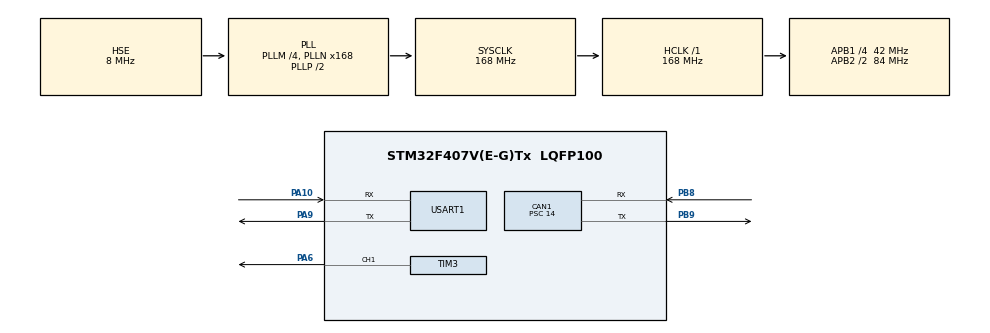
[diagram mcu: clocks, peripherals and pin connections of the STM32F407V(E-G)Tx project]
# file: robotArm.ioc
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CAN1.BS1=CAN_BS1_4TQ
CAN1.CalculateBaudRate=499999
CAN1.CalculateTimeBit=2000
CAN1.CalculateTimeQuantum=333.33333333333337
CAN1.Prescaler=14
FREERTOS.Tasks01=defaultTask,24,2048,StartDefaultTask,Default,NULL,Dynamic,NULL,NULL
FREERTOS.configENABLE_FPU=1
FREERTOS.configTOTAL_HEAP_SIZE=65536
Mcu.Family=STM32F4
Mcu.Name=STM32F407V(E-G)Tx
Mcu.Package=LQFP100
NVIC.CAN1_RX0_IRQn=true\:5\:0\:false\:false\:true\:true\:true\:true\:true
NVIC.CAN1_RX1_IRQn=true\:5\:0\:false\:false\:true\:true\:true\:true\:true
NVIC.PriorityGroup=NVIC_PRIORITYGROUP_4
NVIC.TIM1_UP_TIM10_IRQn=true\:15\:0\:false\:false\:true\:false\:false\:true\:true
NVIC.TimeBase=TIM1_UP_TIM10_IRQn
NVIC.TimeBaseIP=TIM1
NVIC.USART1_IRQn=true\:5\:0\:false\:false\:true\:true\:true\:true\:true
PA10.Mode=Asynchronous
PA10.Signal=USART1_RX
PA13.Mode=JTAG_4_pins
PA13.Signal=SYS_JTMS-SWDIO
PA14.Mode=JTAG_4_pins
PA14.Signal=SYS_JTCK-SWCLK
PA15.Mode=JTAG_4_pins
PA15.Signal=SYS_JTDI
PA6.Signal=S_TIM3_CH1
PA9.Mode=Asynchronous
PA9.Signal=USART1_TX
PB3.Mode=JTAG_4_pins
PB3.Signal=SYS_JTDO-SWO
PB8.Mode=CAN_Activate
PB8.Signal=CAN1_RX
PB9.Mode=CAN_Activate
PB9.Signal=CAN1_TX
PH0-OSC_IN.Mode=HSE-External-Oscillator
PH0-OSC_IN.Signal=RCC_OSC_IN
PH1-OSC_OUT.Mode=HSE-External-Oscillator
PH1-OSC_OUT.Signal=RCC_OSC_OUT
ProjectManager.HeapSize=0x200
ProjectManager.StackSize=0x400
ProjectManager.TargetToolchain=STM32CubeIDE
RCC.48MHZClocksFreq_Value=84000000
RCC.AHBFreq_Value=168000000
RCC.APB1CLKDivider=RCC_HCLK_DIV4
RCC.APB1Freq_Value=42000000
RCC.APB1TimFreq_Value=84000000
RCC.APB2CLKDivider=RCC_HCLK_DIV2
RCC.APB2Freq_Value=84000000
RCC.APB2TimFreq_Value=168000000
RCC.CortexFreq_Value=168000000
RCC.HCLKFreq_Value=168000000
RCC.HSE_VALUE=8000000
RCC.HSI_VALUE=16000000
RCC.LSE_VALUE=32768
RCC.PLLM=4
RCC.PLLN=168
RCC.PLLSourceVirtual=RCC_PLLSOURCE_HSE
RCC.SYSCLKFreq_VALUE=168000000
RCC.SYSCLKSource=RCC_SYSCLKSOURCE_PLLCLK
RCC.VCOOutputFreq_Value=336000000
SH.S_TIM3_CH1.0=TIM3_CH1,PWM Generation1 CH1
TIM3.Channel-PWM\ Generation1\ CH1=TIM_CHANNEL_1
TIM3.Period=19999
TIM3.Prescaler=83
USART1.VirtualMode=VM_ASYNC
VP_FREERTOS_VS_CMSIS_V2.Mode=CMSIS_V2
VP_SYS_VS_tim1.Mode=TIM1
VP_TIM3_VS_ClockSourceINT.Mode=Internal
board=custom

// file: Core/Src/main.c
/* USER CODE BEGIN Header */
/**
  ******************************************************************************
  * @file           : main.c
  * @brief          : Main program body
  ******************************************************************************
  * @attention
  *
  * Copyright (c) 2026 STMicroelectronics.
  * All rights reserved.
  *
  * This software is licensed under terms that can be found in the LICENSE file
  * in the root directory of this software component.
  * If no LICENSE file comes with this software, it is provided AS-IS.
  *
  ******************************************************************************
  */
/* USER CODE END Header */
#include "main.h"
#include "cmsis_os.h"
#include "can.h"
#include "tim.h"
#include "usart.h"
#include "gpio.h"

/* USER CODE BEGIN Includes */
#include "can.h"
#include "Emm_V5.h"
#include "mg996r.h"

/* USER CODE END Includes */

void SystemClock_Config(void);
void MX_FREERTOS_Init(void);

int main(void)
{

  /* MCU Configuration--------------------------------------------------------*/

  /* Reset of all peripherals, Initializes the Flash interface and the Systick. */
  HAL_Init();

  /* Configure the system clock */
  SystemClock_Config();

  /* Initialize all configured peripherals */
  MX_GPIO_Init();
  MX_CAN1_Init();
  MX_USART1_UART_Init();
  MX_TIM3_Init();
  /* USER CODE BEGIN 2 */
  USER_CAN1_Filter_Init();

  if(HAL_CAN_Start(&hcan1) != HAL_OK) { // 启动 CAN 控制器
	  Error_Handler();
  }

  if(HAL_CAN_ActivateNotification(&hcan1, CAN_IT_RX_FIFO0_MSG_PENDING) != HAL_OK) { // 使能 CAN 控制器接收中断
	  Error_Handler();
  }

  // 初始化 MG996R 舵机
  if (MG996R_Init() != HAL_OK) {
	  Error_Handler();
  }
  LOG("MG996R initialized successfully\r\n");

  // === 电机控制 ===
// HAL_Delay(500);  // 等待驱动器就绪
// Emm_V5_Pos_Control(1, 0, 200, 0, 32000, 0, 0);

  /* USER CODE END 2 */

  /* Init scheduler */
  osKernelInitialize();  /* Call init function for freertos objects (in cmsis_os2.c) */
  MX_FREERTOS_Init();

  /* Start scheduler */
  osKernelStart();

  /* We should never get here as control is now taken by the scheduler */

  /* Infinite loop */
  while (1)
  {

  }
}

void SystemClock_Config(void)
{
  RCC_OscInitTypeDef RCC_OscInitStruct = {0};
  RCC_ClkInitTypeDef RCC_ClkInitStruct = {0};

  /** Configure the main internal regulator output voltage
  */
  __HAL_RCC_PWR_CLK_ENABLE();
  __HAL_PWR_VOLTAGESCALING_CONFIG(PWR_REGULATOR_VOLTAGE_SCALE1);

  /** Initializes the RCC Oscillators according to the specified parameters
  * in the RCC_OscInitTypeDef structure.
  */
  RCC_OscInitStruct.OscillatorType = RCC_OSCILLATORTYPE_HSE;
  RCC_OscInitStruct.HSEState = RCC_HSE_ON;
  RCC_OscInitStruct.PLL.PLLState = RCC_PLL_ON;
  RCC_OscInitStruct.PLL.PLLSource = RCC_PLLSOURCE_HSE;
  RCC_OscInitStruct.PLL.PLLM = 4;
  RCC_OscInitStruct.PLL.PLLN = 168;
  RCC_OscInitStruct.PLL.PLLP = RCC_PLLP_DIV2;
  RCC_OscInitStruct.PLL.PLLQ = 4;
  if (HAL_RCC_OscConfig(&RCC_OscInitStruct) != HAL_OK)
  {
    Error_Handler();
  }

  /** Initializes the CPU, AHB and APB buses clocks
  */
  RCC_ClkInitStruct.ClockType = RCC_CLOCKTYPE_HCLK|RCC_CLOCKTYPE_SYSCLK
                              |RCC_CLOCKTYPE_PCLK1|RCC_CLOCKTYPE_PCLK2;
  RCC_ClkInitStruct.SYSCLKSource = RCC_SYSCLKSOURCE_PLLCLK;
  RCC_ClkInitStruct.AHBCLKDivider = RCC_SYSCLK_DIV1;
  RCC_ClkInitStruct.APB1CLKDivider = RCC_HCLK_DIV4;
  RCC_ClkInitStruct.APB2CLKDivider = RCC_HCLK_DIV2;

  if (HAL_RCC_ClockConfig(&RCC_ClkInitStruct, FLASH_LATENCY_5) != HAL_OK)
  {
    Error_Handler();
  }
}

void HAL_TIM_PeriodElapsedCallback(TIM_HandleTypeDef *htim)
{
  if (htim->Instance == TIM1)
  {
    HAL_IncTick();
  }
}

void Error_Handler(void)
{
  __disable_irq();
  while (1)
  {
  }
}

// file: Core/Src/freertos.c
/* USER CODE BEGIN Header */
/**
  ******************************************************************************
  * File Name          : freertos.c
  * Description        : Code for freertos applications
  ******************************************************************************
  * @attention
  *
  * Copyright (c) 2026 STMicroelectronics.
  * All rights reserved.
  *
  * This software is licensed under terms that can be found in the LICENSE file
  * in the root directory of this software component.
  * If no LICENSE file comes with this software, it is provided AS-IS.
  *
  ******************************************************************************
  */
/* USER CODE END Header */

#include "FreeRTOS.h"
#include "task.h"
#include "main.h"
#include "cmsis_os.h"

/* USER CODE BEGIN Includes */
#include "robot.h"
/* USER CODE END Includes */

/* Definitions for defaultTask */
osThreadId_t defaultTaskHandle;
const osThreadAttr_t defaultTask_attributes = {
  .name = "defaultTask",
  .stack_size = 2048 * 4,
  .priority = (osPriority_t) osPriorityNormal,
};

void StartDefaultTask(void *argument);

void MX_FREERTOS_Init(void); /* (MISRA C 2004 rule 8.1) */

void MX_FREERTOS_Init(void) {

  /* Create the thread(s) */
  /* creation of defaultTask */
  defaultTaskHandle = osThreadNew(StartDefaultTask, NULL, &defaultTask_attributes);

}

void StartDefaultTask(void *argument)
{
  /* USER CODE BEGIN StartDefaultTask */
  /* Infinite loop */
  robot_init();
  for(;;)
  {
    osDelay(1);
  }
  /* USER CODE END StartDefaultTask */
}
